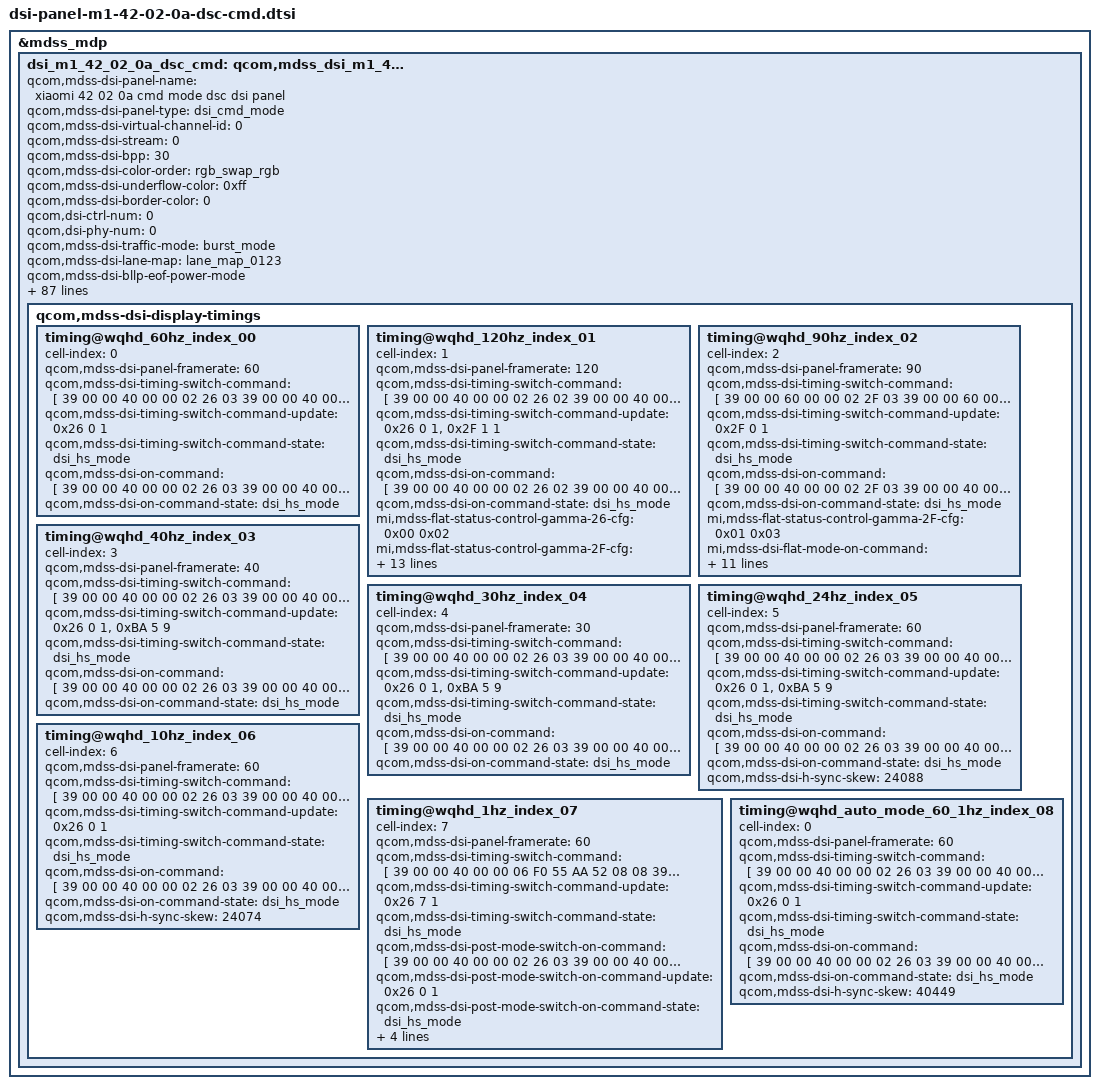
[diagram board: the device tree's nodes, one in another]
&mdss_mdp {
	dsi_m1_42_02_0a_dsc_cmd: qcom,mdss_dsi_m1_42_02_0a_dsc_cmd {
		qcom,mdss-dsi-panel-name = "xiaomi 42 02 0a cmd mode dsc dsi panel";
		qcom,mdss-dsi-panel-type = "dsi_cmd_mode";
		qcom,mdss-dsi-virtual-channel-id = <0>;
		qcom,mdss-dsi-stream = <0>;
		qcom,mdss-dsi-bpp = <30>;
		qcom,mdss-dsi-color-order = "rgb_swap_rgb";
		qcom,mdss-dsi-underflow-color = <0xff>;
		qcom,mdss-dsi-border-color = <0>;
		qcom,dsi-ctrl-num = <0>;
		qcom,dsi-phy-num = <0>;

		qcom,mdss-dsi-traffic-mode = "burst_mode";
		qcom,mdss-dsi-lane-map = "lane_map_0123";
		qcom,mdss-dsi-bllp-eof-power-mode;
		qcom,mdss-dsi-bllp-power-mode;
		qcom,mdss-dsi-lane-0-state;
		qcom,mdss-dsi-lane-1-state;
		qcom,mdss-dsi-lane-2-state;
		qcom,mdss-dsi-lane-3-state;
		qcom,mdss-dsi-dma-trigger = "trigger_sw";
		qcom,mdss-dsi-mdp-trigger = "none";
		qcom,mdss-dsi-reset-sequence =<1 1>, <0 1>, <1 10>;
		qcom,mdss-pan-physical-width-dimension = <701>;
		qcom,mdss-pan-physical-height-dimension = <1558>;
		qcom,mdss-dsi-te-pin-select = <1>;
		qcom,mdss-dsi-wr-mem-start = <0x2c>;
		qcom,mdss-dsi-wr-mem-continue = <0x3c>;
		qcom,mdss-dsi-te-dcs-command = <1>;
		qcom,mdss-dsi-te-check-enable;
		qcom,mdss-dsi-te-using-te-pin;
		qcom,mdss-dsi-tx-eot-append;
		qcom,mdss-dsi-lp11-init;

		qcom,mdss-dsi-bl-inverted-dbv;
		qcom,bl-update-flag = "delay_until_first_frame";

		qcom,mdss-dsi-panel-hdr-enabled;
		qcom,mdss-dsi-panel-hdr-color-primaries = <14500 15500 32000
			17000 15500 30000 8000 3000>;
		qcom,mdss-dsi-panel-peak-brightness = <9000000>;
		qcom,mdss-dsi-panel-blackness-level = <3230>;

		qcom,mdss-dsi-dma-schedule-line = <1>;
		qcom,mdss-dsi-dma-schedule-window = <50>;

		/* IRQF_ONESHOT | IRQF_TRIGGER_LOW */
		mi,esd-err-irq-gpio = <&tlmm 54 0x2008>;
		mi,panel-id = <0x00004D31 0x00420200>;
		qcom,esd-check-enabled;
		qcom,mdss-dsi-panel-status-check-mode = "reg_read";
		qcom,mdss-dsi-panel-status-command = [06 01 00 01 00 00 01 91];
		qcom,mdss-dsi-panel-status-command-state = "dsi_hs_mode";
		qcom,mdss-dsi-panel-status-value = <0xAB 0xA8>;
		qcom,mdss-dsi-panel-status-read-length = <2>;

		//mi,ddic-round-corner-enabled;
		mi,local-hbm-enabled;

		mi,local-hbm-ui-ready-delay-num-frame = <2>; /* 2 frame */
		mi,fod-low-brightness-clone-threshold = <411>;
		mi,fod-low-brightness-lux-threshold = <1>;
		mi,need-fod-animal-in-normal-enabled;

		mi,panel-on-dimming-delay = <120>;
		mi,max-brightness-clone = <16383>;
		mi,normal-max-brightness-clone = <8191>;
		mi,thermal-dimming-flag;

		mi,mdss-dsi-fac-bl-max-level = <2047>;
		mi,mdss-fac-brightness-max-level = <2047>;
		mi,doze-hbm-dbv-level = <245>;
		mi,doze-lbm-dbv-level = <20>;

		mi,flatmode-status-check-enabled;
		mi,mdss-dsi-panel-flatmode-status-command = [
			06 01 00 01 00 00 01 5F
		];
		mi,mdss-dsi-panel-flatmode-status-command-state = "dsi_hs_mode";
		mi,mdss-dsi-panel-flatmode-status-read-length = <1>;
		mi,mdss-dsi-panel-flatmode-on-status-value = <0x00>;

		mi,mdss-dsi-panel-wp-read-command = [06 01 00 01 00 00 01 A3];
		mi,mdss-dsi-panel-wp-read-command-state = "dsi_hs_mode";
		mi,mdss-dsi-panel-wp-read-length = <8>;
		qcom,mdss-dsi-display-timings {
			timing@wqhd_60hz_index_00 {
				cell-index = <0>;
				#include "dsi-panel-m1-42-02-0a-dsc-cmd-common.dtsi"
				qcom,mdss-dsi-panel-framerate = <60>;

				qcom,mdss-dsi-timing-switch-command = [
					/*120HZ*/
					39 00 00 40 00 00 02 26 03
					39 00 00 40 00 00 02 2F 00
					/*60HZ*/
					39 00 00 40 00 00 02 2F 30
					39 00 00 40 00 00 06 F0 55 AA 52 08 00
					39 00 00 40 00 00 02 6F 1C
					39 00 00 40 00 00 0A BA 91 01 01 00 01 01 01 00 00
					39 00 00 40 00 00 02 BC 20
					39 00 00 00 00 00 02 2C 00
				];
				qcom,mdss-dsi-timing-switch-command-update = <0x26 0 1>;
				qcom,mdss-dsi-timing-switch-command-state = "dsi_hs_mode";

				qcom,mdss-dsi-on-command = [
					#include "dsi-panel-m1-42-02-0a-dsc-cmd-dsi-on-common.dtsi"
					/*120HZ*/
					39 00 00 40 00 00 02 26 03
					39 00 00 40 00 00 02 2F 00
					/*60HZ*/
					39 00 00 40 00 00 02 2F 30
					39 00 00 40 00 00 06 F0 55 AA 52 08 00
					39 00 00 40 00 00 02 6F 1C
					39 00 00 40 00 00 0A BA 91 01 01 00 01 01 01 00 00
					39 00 00 40 00 00 02 BC 20
					39 00 00 40 00 00 02 2C 00
					/* Sleep Out */
					05 00 00 00 78 00 01 11
					/*black mask off*/
					39 00 00 40 00 00 06 F0 55 AA 52 08 02
					39 00 00 40 00 00 02 CC 10
					/* Display On */
					05 00 00 00 00 00 01 29
				];
				qcom,mdss-dsi-on-command-state = "dsi_hs_mode";
			};

			timing@wqhd_120hz_index_01 {
				cell-index = <1>;
				#include "dsi-panel-m1-42-02-0a-dsc-cmd-common.dtsi"
				qcom,mdss-dsi-panel-framerate = <120>;

				qcom,mdss-dsi-timing-switch-command = [
					/* 120Hz */
					39 00 00 40 00 00 02 26 02
					39 00 00 40 00 00 02 2F 02
					39 00 00 40 00 00 06 F0 55 AA 52 08 00
					39 00 00 40 00 00 02 BC 00
					39 00 00 00 00 00 02 2C 00
				];
				qcom,mdss-dsi-timing-switch-command-update = <0x26 0 1>,<0x2F 1 1>;
				qcom,mdss-dsi-timing-switch-command-state = "dsi_hs_mode";

				qcom,mdss-dsi-on-command = [
					#include "dsi-panel-m1-42-02-0a-dsc-cmd-dsi-on-common.dtsi"
					/* 120Hz */
					39 00 00 40 00 00 02 26 02
					39 00 00 40 00 00 02 2F 02
					39 00 00 40 00 00 06 F0 55 AA 52 08 00
					39 00 00 40 00 00 02 BC 00
					39 00 00 40 00 00 02 2C 00
					/* Sleep Out */
					05 00 00 00 78 00 01 11
					39 00 00 40 00 00 06 F0 55 AA 52 08 02
					39 00 00 40 00 00 02 CC 10
					/* Display On */
					05 00 00 00 00 00 01 29
				];
				qcom,mdss-dsi-on-command-state = "dsi_hs_mode";
			};

			timing@wqhd_90hz_index_02 {
				cell-index = <2>;
				#include "dsi-panel-m1-42-02-0a-dsc-cmd-common.dtsi"
				qcom,mdss-dsi-panel-framerate = <90>;

				qcom,mdss-dsi-timing-switch-command = [
					39 00 00 60 00 00 02 2F 03
					39 00 00 60 00 00 06 F0 55 AA 52 08 00
					39 00 00 20 00 00 02 BC 00
				];
				qcom,mdss-dsi-timing-switch-command-update = <0x2F 0 1>;
				qcom,mdss-dsi-timing-switch-command-state = "dsi_hs_mode";

				qcom,mdss-dsi-on-command = [
					#include "dsi-panel-m1-42-02-0a-dsc-cmd-dsi-on-common.dtsi"
					/* 90HZ */
					39 00 00 40 00 00 02 2F 03
					39 00 00 40 00 00 06 F0 55 AA 52 08 00
					39 00 00 40 00 00 02 BC 00
					/* Sleep Out */
					05 00 00 00 78 00 01 11
					39 00 00 40 00 00 06 F0 55 AA 52 08 02
					39 00 00 40 00 00 02 CC 10
					/* Display On */
					05 00 00 00 00 00 01 29
				];
				qcom,mdss-dsi-on-command-state = "dsi_hs_mode";
			};

			timing@wqhd_40hz_index_03 {
				cell-index = <3>;
				#include "dsi-panel-m1-42-02-0a-dsc-cmd-common.dtsi"
				qcom,mdss-dsi-panel-framerate = <40>;

				qcom,mdss-dsi-timing-switch-command = [
					/*120HZ*/
					39 00 00 40 00 00 02 26 03
					39 00 00 40 00 00 02 2F 00
					/*40HZ*/
					39 00 00 40 00 00 02 2F 30
					39 00 00 40 00 00 06 F0 55 AA 52 08 00
					39 00 00 40 00 00 02 6F 1C
					39 00 00 40 00 00 0A BA 91 01 01 00 01 02 02 00 00
					39 00 00 40 00 00 02 BC 40
					39 00 00 00 00 00 02 2C 00
				];
				qcom,mdss-dsi-timing-switch-command-update = <0x26 0 1>, <0xBA 5 9>;
				qcom,mdss-dsi-timing-switch-command-state = "dsi_hs_mode";

				qcom,mdss-dsi-on-command = [
					#include "dsi-panel-m1-42-02-0a-dsc-cmd-dsi-on-common.dtsi"
					/*120HZ*/
					39 00 00 40 00 00 02 26 03
					39 00 00 40 00 00 02 2F 00
					/*40HZ*/
					39 00 00 40 00 00 02 2F 30
					39 00 00 40 00 00 06 F0 55 AA 52 08 00
					39 00 00 40 00 00 02 6F 1C
					39 00 00 40 00 00 0A BA 91 01 01 00 01 02 02 00 00
					39 00 00 40 00 00 02 BC 40
					39 00 00 40 00 00 02 2C 00
					/* Sleep Out */
					05 00 00 00 78 00 01 11
					/*black mask off*/
					39 00 00 40 00 00 06 F0 55 AA 52 08 02
					39 00 00 40 00 00 02 CC 10
					/* Display On */
					05 00 00 00 00 00 01 29
				];
				qcom,mdss-dsi-on-command-state = "dsi_hs_mode";
			};

			timing@wqhd_30hz_index_04 {
				cell-index = <4>;
				#include "dsi-panel-m1-42-02-0a-dsc-cmd-common.dtsi"
				qcom,mdss-dsi-panel-framerate = <30>;

				qcom,mdss-dsi-timing-switch-command = [
					/*120HZ*/
					39 00 00 40 00 00 02 26 03
					39 00 00 40 00 00 02 2F 00
					/*30HZ*/
					39 00 00 40 00 00 02 2F 30
					39 00 00 40 00 00 06 F0 55 AA 52 08 00
					39 00 00 40 00 00 02 6F 1C
					39 00 00 40 00 00 0A BA 91 01 01 00 01 03 03 00 00
					39 00 00 40 00 00 02 BC 60
					39 00 00 00 00 00 02 2C 00
				];
				qcom,mdss-dsi-timing-switch-command-update = <0x26 0 1>, <0xBA 5 9>;
				qcom,mdss-dsi-timing-switch-command-state = "dsi_hs_mode";

				qcom,mdss-dsi-on-command = [
					#include "dsi-panel-m1-42-02-0a-dsc-cmd-dsi-on-common.dtsi"
					/*120HZ*/
					39 00 00 40 00 00 02 26 03
					39 00 00 40 00 00 02 2F 00
					/*30HZ*/
					39 00 00 40 00 00 02 2F 30
					39 00 00 40 00 00 06 F0 55 AA 52 08 00
					39 00 00 40 00 00 02 6F 1C
					39 00 00 40 00 00 0A BA 91 02 01 00 01 03 03 00 00
					39 00 00 40 00 00 02 BC 60
					39 00 00 40 00 00 02 2C 00
					/* Sleep Out */
					05 00 00 00 78 00 01 11
					/*black mask off*/
					39 00 00 40 00 00 06 F0 55 AA 52 08 02
					39 00 00 40 00 00 02 CC 10
					/* Display On */
					05 00 00 00 00 00 01 29
				];
				qcom,mdss-dsi-on-command-state = "dsi_hs_mode";
			};

			timing@wqhd_24hz_index_05 {
				cell-index = <5>;
				#include "dsi-panel-m1-42-02-0a-dsc-cmd-common.dtsi"
				qcom,mdss-dsi-panel-framerate = <60>;

				qcom,mdss-dsi-timing-switch-command = [
					/*120HZ*/
					39 00 00 40 00 00 02 26 03
					39 00 00 40 00 00 02 2F 00
					/*24HZ*/
					39 00 00 40 00 00 02 2F 30
					39 00 00 40 00 00 06 F0 55 AA 52 08 00
					39 00 00 40 00 00 02 6F 1C
					39 00 00 40 00 00 0A BA 91 03 01 00 11 04 04 00 05
					39 00 00 40 00 00 02 BC 20
					39 00 00 00 00 00 02 2C 00
				];
				qcom,mdss-dsi-timing-switch-command-update = <0x26 0 1>, <0xBA 5 9>;
				qcom,mdss-dsi-timing-switch-command-state = "dsi_hs_mode";

				qcom,mdss-dsi-on-command = [
					#include "dsi-panel-m1-42-02-0a-dsc-cmd-dsi-on-common.dtsi"
					/*120HZ*/
					39 00 00 40 00 00 02 26 03
					39 00 00 40 00 00 02 2F 00
					/*24HZ*/
					39 00 00 40 00 00 02 2F 30
					39 00 00 40 00 00 06 F0 55 AA 52 08 00
					39 00 00 40 00 00 02 6F 1C
					39 00 00 40 00 00 0A BA 91 03 01 00 11 04 04 00 05
					39 00 00 40 00 00 02 BC 20
					39 00 00 40 00 00 02 2C 00
					/* Sleep Out */
					05 00 00 00 78 00 01 11
					/*black mask off*/
					39 00 00 40 00 00 06 F0 55 AA 52 08 02
					39 00 00 40 00 00 02 CC 10
					/* Display On */
					05 00 00 00 00 00 01 29
				];
				qcom,mdss-dsi-on-command-state = "dsi_hs_mode";
			};

			timing@wqhd_10hz_index_06 {
				cell-index = <6>;
				#include "dsi-panel-m1-42-02-0a-dsc-cmd-common.dtsi"
				qcom,mdss-dsi-panel-framerate = <60>;

				qcom,mdss-dsi-timing-switch-command = [
					/*120HZ*/
					39 00 00 40 00 00 02 26 03
					39 00 00 40 00 00 02 2F 00
					/*10HZ*/
					39 00 00 40 00 00 02 2F 30
					39 00 00 40 00 00 06 F0 55 AA 52 08 00
					39 00 00 40 00 00 02 6F 1C
					39 00 00 40 00 00 0A BA 91 0B 01 00 11 0B 0B 00 05
					39 00 00 40 00 00 02 BC 20
					39 00 00 00 00 00 02 2C 00
				];
				qcom,mdss-dsi-timing-switch-command-update = <0x26 0 1>;
				qcom,mdss-dsi-timing-switch-command-state = "dsi_hs_mode";

				qcom,mdss-dsi-on-command = [
					#include "dsi-panel-m1-42-02-0a-dsc-cmd-dsi-on-common.dtsi"
					/*120HZ*/
					39 00 00 40 00 00 02 26 03
					39 00 00 40 00 00 02 2F 00
					/*10HZ*/
					39 00 00 40 00 00 02 2F 30
					39 00 00 40 00 00 06 F0 55 AA 52 08 00
					39 00 00 40 00 00 02 6F 1C
					39 00 00 40 00 00 0A BA 91 0B 01 00 11 0B 0B 00 05
					39 00 00 40 00 00 02 BC 20
					39 00 00 40 00 00 02 2C 00
					/* Sleep Out */
					05 00 00 00 78 00 01 11
					/*black mask off*/
					39 00 00 40 00 00 06 F0 55 AA 52 08 02
					39 00 00 40 00 00 02 CC 10
					/* Display On */
					05 00 00 00 00 00 01 29
				];
				qcom,mdss-dsi-on-command-state = "dsi_hs_mode";
			};

			timing@wqhd_1hz_index_07 {
				cell-index = <7>;
				#include "dsi-panel-m1-42-02-0a-dsc-cmd-common.dtsi"
				qcom,mdss-dsi-panel-framerate = <60>;

				qcom,mdss-dsi-timing-switch-command = [
					39 00 00 40 00 00 06 F0 55 AA 52 08 08
					39 00 00 40 00 00 0F CB 00 00 00 00 00 00 00 00 00 00 00 00 00 00
					39 00 00 40 00 00 0F CC 00 00 00 00 00 00 00 00 00 00 00 00 00 00
					39 00 00 40 00 00 0F CE 00 00 00 00 00 00 00 00 00 00 00 00 00 00
					39 00 00 40 00 00 06 F0 55 AA 52 08 08
					39 00 00 40 00 00 02 6F 07
					39 00 00 40 00 00 05 D3 00 00 00 00
					/*120HZ*/
					39 00 00 40 00 00 02 26 03
					39 00 00 40 00 00 02 2F 00
					/*60HZ*/
					39 00 00 40 00 00 02 2F 30
					39 00 00 40 00 00 06 F0 55 AA 52 08 00
					39 00 00 40 00 00 02 6F 1C
					39 00 00 40 00 00 0A BA 91 01 01 00 01 01 01 00 00
					39 00 00 40 00 00 02 BC 20
					39 00 00 00 00 00 02 2C 00
				];
				qcom,mdss-dsi-timing-switch-command-update = <0x26 7 1>;
				qcom,mdss-dsi-timing-switch-command-state = "dsi_hs_mode";

				qcom,mdss-dsi-post-mode-switch-on-command = [
					/*120HZ*/
					39 00 00 40 00 00 02 26 03
					39 00 00 40 00 00 02 2F 00
					/*1HZ*/
					39 00 00 40 00 00 02 2F 30
					39 00 00 40 00 00 06 F0 55 AA 52 08 00
					39 00 00 40 00 00 02 6F 1C
					39 00 00 40 00 00 0A BA 91 0B 01 00 11 77 77 00 05
					39 00 00 40 00 00 02 BC 20
					39 00 00 00 00 00 02 2C 00
				];
				qcom,mdss-dsi-post-mode-switch-on-command-update = <0x26 0 1>;
				qcom,mdss-dsi-post-mode-switch-on-command-state = "dsi_hs_mode";

				qcom,mdss-dsi-on-command = [
					#include "dsi-panel-m1-42-02-0a-dsc-cmd-dsi-on-common.dtsi"
					/*120HZ*/
					39 00 00 40 00 00 02 26 03
					39 00 00 40 00 00 02 2F 00
					/*1HZ*/
					39 00 00 40 00 00 02 2F 30
					39 00 00 40 00 00 06 F0 55 AA 52 08 00
					39 00 00 40 00 00 02 6F 1C
					39 00 00 40 00 00 0A BA 91 0B 01 00 11 77 77 00 05
					39 00 00 40 00 00 02 BC 20
					39 00 00 40 00 00 02 2C 00
					/* Sleep Out */
					05 00 00 00 78 00 01 11
					/*black mask off*/
					39 00 00 40 00 00 06 F0 55 AA 52 08 02
					39 00 00 40 00 00 02 CC 10
					/* Display On */
					05 00 00 00 00 00 01 29
				];
				qcom,mdss-dsi-on-command-state = "dsi_hs_mode";

			};
			timing@wqhd_auto_mode_60_1hz_index_08 {
				cell-index = <0>;
				#include "dsi-panel-m1-42-02-0a-dsc-cmd-common.dtsi"
				qcom,mdss-dsi-panel-framerate = <60>;

				qcom,mdss-dsi-timing-switch-command = [
					/*120HZ*/
					39 00 00 40 00 00 02 26 03
					39 00 00 40 00 00 02 2F 00
					/*60-1HZ auto mode*/
					39 00 00 40 00 00 02 2F 30
					39 00 00 40 00 00 06 F0 55 AA 52 08 00
					39 00 00 40 00 00 02 6F 1C
					39 00 00 40 00 00 0A BA 91 0B 01 00 11 77 77 00 05
					39 00 00 40 00 00 02 BC 20
					39 00 00 00 00 00 02 2C 00
				];
				qcom,mdss-dsi-timing-switch-command-update = <0x26 0 1>;
				qcom,mdss-dsi-timing-switch-command-state = "dsi_hs_mode";

				qcom,mdss-dsi-on-command = [
					#include "dsi-panel-m1-42-02-0a-dsc-cmd-dsi-on-common.dtsi"
					/*120HZ*/
					39 00 00 40 00 00 02 26 03
					39 00 00 40 00 00 02 2F 00
					/*60-1HZ auto mode*/
					39 00 00 40 00 00 02 2F 30
					39 00 00 40 00 00 06 F0 55 AA 52 08 00
					39 00 00 40 00 00 02 6F 1C
					39 00 00 40 00 00 0A BA 91 0B 03 00 11 77 77 00 05
					39 00 00 40 00 00 02 BC 20
					39 00 00 40 00 00 02 2C 00
					/* Sleep Out */
					05 00 00 00 78 00 01 11
					/*black mask off*/
					39 00 00 40 00 00 06 F0 55 AA 52 08 02
					39 00 00 40 00 00 02 CC 10
					/* Display On */
					05 00 00 00 00 00 01 29
				];
				qcom,mdss-dsi-on-command-state = "dsi_hs_mode";
			};
		};
	};
};

&dsi_m1_42_02_0a_dsc_cmd {
	qcom,mdss-dsi-panel-vsync-delay;
	qcom,ulps-enabled;
	qcom,dsi-select-clocks = "pll_byte_clk0", "pll_dsi_clk0";
	qcom,mdss-dsi-clk-strength = <0xFF>;
	qcom,mdss-dsi-display-timings {
		/* WQHD 120hz */
		timing@wqhd_120hz_index_01{
			/*<flat on gamma, flat off gamma>*/
			mi,mdss-flat-status-control-gamma-26-cfg  = <0x00 0x02>;
			mi,mdss-flat-status-control-gamma-2F-cfg  = <0x00 0x02>;

			mi,mdss-dsi-flat-mode-on-command = [
				39 00 00 40 00 00 02 26 00
				39 00 00 40 00 00 02 2F 00
				39 00 00 00 00 00 02 5F 00
			];
			mi,mdss-dsi-flat-mode-on-command-update = <0x26 0 1>, <0x2F 1 1>;
			mi,mdss-dsi-flat-mode-on-command-state = "dsi_hs_mode";

			mi,mdss-dsi-flat-mode-off-command = [
				39 00 00 40 00 00 02 26 02
				39 00 00 40 00 00 02 2F 02
				39 00 00 00 00 00 02 5F 01
			];
			mi,mdss-dsi-flat-mode-off-command-update = <0x26 0 1>, <0x2F 1 1>;
			mi,mdss-dsi-flat-mode-off-command-state = "dsi_hs_mode";
		};
		/* WQHD 90hz */
		timing@wqhd_90hz_index_02{
			/*<flat on gamma, flat off gamma>*/
			mi,mdss-flat-status-control-gamma-2F-cfg = <0x01 0x03>;

			mi,mdss-dsi-flat-mode-on-command = [
				39 00 00 40 00 00 02 2F 01
				39 00 00 00 00 00 02 5F 00
			];
			mi,mdss-dsi-flat-mode-on-command-update = <0x2F 0 1>;
			mi,mdss-dsi-flat-mode-on-command-state = "dsi_hs_mode";

			mi,mdss-dsi-flat-mode-off-command = [
				39 00 00 40 00 00 02 2F 03
				39 00 00 00 00 00 02 5F 01
			];
			mi,mdss-dsi-flat-mode-off-command-update = <0x2F 0 1>;
			mi,mdss-dsi-flat-mode-off-command-state = "dsi_hs_mode";
		};
		/* WQHD 24hz */
		timing@wqhd_24hz_index_05{
			/* ---------------------------- */
			/* | 15 - 14 | 13 - 7 | 6 - 0 | */
			/* ---------------------------- */
			/* |   mode  | sf fps | min fps| */
			/* ---------------------------- -*/
			/* mode: 1 idle, 2 auto, 3 qsync */
			/*   1 << 14 | 60 << 7 | 24     */
			qcom,mdss-dsi-h-sync-skew = <24088>;
		};
		/* WQHD 10hz */
		timing@wqhd_10hz_index_06{
			/* ---------------------------- */
			/* | 15 - 14 | 13 - 7 | 6 - 0 | */
			/* ---------------------------- */
			/* |   mode  | sf fps | min fps| */
			/* ---------------------------- -*/
			/* mode: 1 idle, 2 auto, 3 qsync */
			/*   1 << 14 | 60 << 7 | 10     */
			qcom,mdss-dsi-h-sync-skew = <24074>;
		};
		/* WQHD 1hz */
		timing@wqhd_1hz_index_07{
			/* ---------------------------- */
			/* | 15 - 14 | 13 - 7 | 6 - 0 | */
			/* ---------------------------- */
			/* |   mode  | sf fps | min fps| */
			/* ---------------------------- -*/
			/* mode: 1 idle, 2 auto, 3 qsync */
			/*   1 << 14 | 60 << 7 | 1     */
			qcom,mdss-dsi-h-sync-skew = <24065>;
		};
		timing@wqhd_auto_mode_60_1hz_index_08{
			/* ---------------------------- */
			/* | 15 - 14 | 13 - 7 | 6 - 0 | */
			/* ---------------------------- */
			/* |   mode  | sf fps | min fps| */
			/* ---------------------------- -*/
			/* mode: 1 idle, 2 auto, 3 qsync */
			/*   2 << 14 | 60 << 7 | 1*/
			/*   10 0111100 0000001 */
			qcom,mdss-dsi-h-sync-skew = <40449>;
		};
	};
};

&dsi_m1_42_02_0a_dsc_cmd {
	qcom,panel-supply-entries = <&dsi_panel_pwr_supply_M1>;
	qcom,mdss-dsi-bl-pmic-control-type = "bl_ctrl_dcs";
	qcom,mdss-dsi-bl-min-level = <4>;
	qcom,mdss-dsi-bl-max-level = <4095>;
	qcom,bl-dsc-cmd-state = "dsi_hs_mode";
	qcom,mdss-brightness-max-level = <4095>;
	qcom,mdss-brightness-init-level = <307>;
	qcom,platform-reset-gpio = <&tlmm 69 0>;

	mi,panel-build-id-read-needed;
	mi,panel-build-id-read-length = <1>;
	mi,mdss-dsi-panel-build-id-read-command = [06 01 00 01 00 00 01 DA];
	mi,mdss-dsi-panel-build-id-read-command-state = "dsi_hs_mode";

	mi,disable-ic-dimming-flag;
};

/*Vrr set by DBV*/
&dsi_m1_42_02_0a_dsc_cmd {
	qcom,mdss-dsi-display-timings {
	/* WQHD 60Hz */
		timing@wqhd_60hz_index_00{
			#include "dsi-panel-m1-42-02-0a-dsc-cmd-skip-source-common.dtsi"
			#include "dsi-panel-m1-42-02-0a-dsc-cmd-dbi-bwg-common.dtsi"
			#include "dsi-panel-m1-42-02-0a-dsc-cmd-dbi-bwg-lgs-cie.dtsi"
		};
		/* WQHD 120hz */
		timing@wqhd_120hz_index_01{
			#include "dsi-panel-m1-42-02-0a-dsc-cmd-skip-source-common.dtsi"
			#include "dsi-panel-m1-42-02-0a-dsc-cmd-dbi-bwg-common.dtsi"
			#include "dsi-panel-m1-42-02-0a-dsc-cmd-dbi-bwg-lgs-cie.dtsi"
		};
		/* WQHD 90hz */
		timing@wqhd_90hz_index_02{
			#include "dsi-panel-m1-42-02-0a-dsc-cmd-skip-source-common.dtsi"
			#include "dsi-panel-m1-42-02-0a-dsc-cmd-dbi-bwg-common.dtsi"
			#include "dsi-panel-m1-42-02-0a-dsc-cmd-dbi-bwg-lgs-cie.dtsi"
		};
		/* WQHD 40hz */
		timing@wqhd_40hz_index_03{
			#include "dsi-panel-m1-42-02-0a-dsc-cmd-skip-source-common.dtsi"
			#include "dsi-panel-m1-42-02-0a-dsc-cmd-dbi-bwg-30HZ.dtsi"
		};
		/* WQHD 30hz */
		timing@wqhd_30hz_index_04{
			#include "dsi-panel-m1-42-02-0a-dsc-cmd-skip-source-common.dtsi"
			#include "dsi-panel-m1-42-02-0a-dsc-cmd-dbi-bwg-30HZ.dtsi"
		};
		/* WQHD 24hz */
		timing@wqhd_24hz_index_05{
			#include "dsi-panel-m1-42-02-0a-dsc-cmd-skip-source-common.dtsi"
			#include "dsi-panel-m1-42-02-0a-dsc-cmd-dbi-bwg-30HZ.dtsi"
		};
		/* WQHD 10hz */
		timing@wqhd_10hz_index_06{
			#include "dsi-panel-m1-42-02-0a-dsc-cmd-skip-source-common.dtsi"
			#include "dsi-panel-m1-42-02-0a-dsc-cmd-dbi-bwg-10HZ.dtsi"
		};
		/* WQHD 1hz */
		timing@wqhd_1hz_index_07{
			#include "dsi-panel-m1-42-02-0a-dsc-cmd-skip-source-common.dtsi"
			#include "dsi-panel-m1-42-02-0a-dsc-cmd-dbi-bwg-1HZ.dtsi"
		};
		/*Auto 60-1HZ*/
		timing@wqhd_auto_mode_60_1hz_index_08{
			#include "dsi-panel-m1-42-02-0a-dsc-cmd-skip-source-common.dtsi"
			#include "dsi-panel-m1-42-02-0a-dsc-cmd-dbi-bwg-1HZ.dtsi"
		};
	};
};
